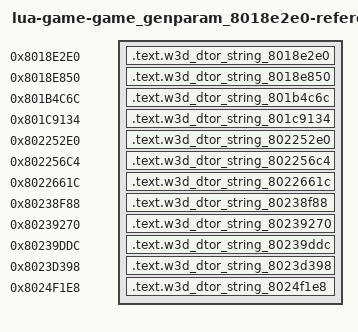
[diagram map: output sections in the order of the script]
/* Generated reference-only placements. All bodies are source-built. */
OUTPUT_FORMAT("elf32-powerpc")
OUTPUT_ARCH(powerpc)
ENTRY(w3d_dtor_string_8018e2e0)
_SDA_BASE_ = 0x804b2540;
_SDA2_BASE_ = 0x804c2540;
fn_8018e2e0 = 0x8018e2e0;
fn_801ea138 = 0x801ea138;
fn_801ea740 = 0x801ea740;
fn_8020c5c4 = 0x8020c5c4;
fn_8021f234 = 0x8021f234;
fn_8021fe20 = 0x8021fe20;
fn_80238dcc = 0x80238dcc;
fn_8023b5f0 = 0x8023b5f0;
fn_80341588 = 0x80341588;
w3d_vtable_80413160 = 0x80413160;
w3d_vtable_804131d8 = 0x804131d8;
w3d_vtable_804145c8 = 0x804145c8;
w3d_vtable_804163c0 = 0x804163c0;
w3d_vtable_8041a258 = 0x8041a258;
w3d_vtable_8041a2f8 = 0x8041a2f8;
w3d_vtable_8041a348 = 0x8041a348;
w3d_vtable_8041ac20 = 0x8041ac20;
w3d_vtable_8041af40 = 0x8041af40;
w3d_vtable_8041b058 = 0x8041b058;
w3d_vtable_8041b080 = 0x8041b080;
w3d_vtable_8041b758 = 0x8041b758;
SECTIONS {
  .text.w3d_dtor_string_8018e2e0 0x8018e2e0 : { *(.text.w3d_dtor_string_8018e2e0) }
  .text.w3d_dtor_string_8018e850 0x8018e850 : { *(.text.w3d_dtor_string_8018e850) }
  .text.w3d_dtor_string_801b4c6c 0x801b4c6c : { *(.text.w3d_dtor_string_801b4c6c) }
  .text.w3d_dtor_string_801c9134 0x801c9134 : { *(.text.w3d_dtor_string_801c9134) }
  .text.w3d_dtor_string_802252e0 0x802252e0 : { *(.text.w3d_dtor_string_802252e0) }
  .text.w3d_dtor_string_802256c4 0x802256c4 : { *(.text.w3d_dtor_string_802256c4) }
  .text.w3d_dtor_string_8022661c 0x8022661c : { *(.text.w3d_dtor_string_8022661c) }
  .text.w3d_dtor_string_80238f88 0x80238f88 : { *(.text.w3d_dtor_string_80238f88) }
  .text.w3d_dtor_string_80239270 0x80239270 : { *(.text.w3d_dtor_string_80239270) }
  .text.w3d_dtor_string_80239ddc 0x80239ddc : { *(.text.w3d_dtor_string_80239ddc) }
  .text.w3d_dtor_string_8023d398 0x8023d398 : { *(.text.w3d_dtor_string_8023d398) }
  .text.w3d_dtor_string_8024f1e8 0x8024f1e8 : { *(.text.w3d_dtor_string_8024f1e8) }
  /DISCARD/ : { *(.text*) *(.rodata*) *(.data*) *(.bss*) *(.sdata*) *(.sbss*) *(.comment) }
}
